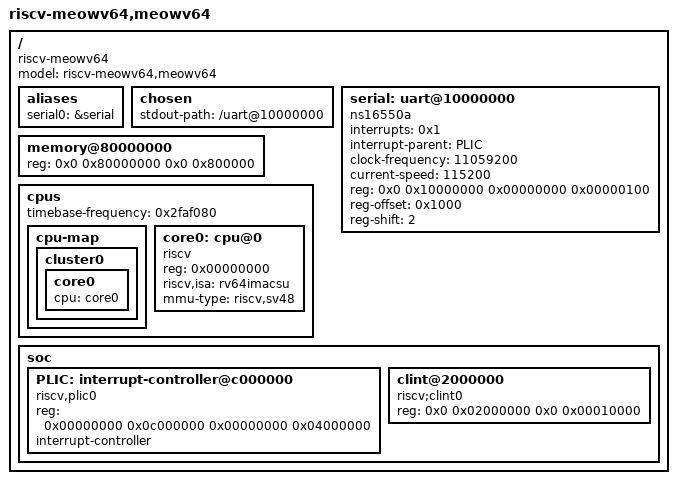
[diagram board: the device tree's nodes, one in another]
/dts-v1/;

/ {
  #address-cells = <0x2>;
  #size-cells = <0x2>;

  compatible = "riscv-meowv64";
  model = "riscv-meowv64,meowv64";

  aliases {
    serial0 = &serial;
  };

  chosen {
    stdout-path = "/uart@10000000";
  };

  serial: uart@10000000 {
    interrupts = <0x1>;
    interrupt-parent = < &PLIC >;
    clock-frequency = <11059200>;
    current-speed = <115200>;
    reg = <0x0 0x10000000 0x00000000 0x00000100>;
    reg-offset=<0x1000>;
    reg-shift=<2>;
    compatible = "ns16550a";
  };

  memory@80000000 {
    device_type = "memory";
    reg = <0x0 0x80000000 0x0 0x800000>;
  };

  cpus {
    #address-cells = <0x00000001>;
    #size-cells = <0x00000000>;
    timebase-frequency = <0x2faf080>; // 50M
    cpu-map {
      cluster0 {
        core0 {
          cpu = <&core0>;
        };
      };
    };
    core0: cpu@0 {
      device_type = "cpu";
      reg = <0x00000000>;
      status = "okay";
      compatible = "riscv";
      riscv,isa = "rv64imacsu";
      mmu-type = "riscv,sv48";
    };
  };

  soc {
    #address-cells = <0x2>;
    #size-cells = <0x2>;

    PLIC: interrupt-controller@c000000 {
      #interrupt-cells = <0x00000001>;
      reg = <0x00000000 0x0c000000 0x00000000 0x04000000>;
      interrupt-controller;
      compatible = "riscv,plic0";
    };

    clint@2000000 {
      reg = <0x0 0x02000000 0x0 0x00010000>;
      compatible = "riscv;clint0";
    };
  };
};
